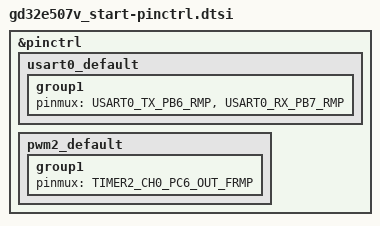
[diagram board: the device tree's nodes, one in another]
/*
 * Copyright (c) 2022, Teslabs Engineering S.L.
 * SPDX-License-Identifier: Apache-2.0
 */

#include <dt-bindings/pinctrl/gd32e507v(e-c)xx-pinctrl.h>

&pinctrl {
	usart0_default: usart0_default {
		group1 {
			pinmux = <USART0_TX_PB6_RMP>, <USART0_RX_PB7_RMP>;
		};
	};

	pwm2_default: pwm2_default {
		group1 {
			pinmux = <TIMER2_CH0_PC6_OUT_FRMP>;
		};
	};
};
